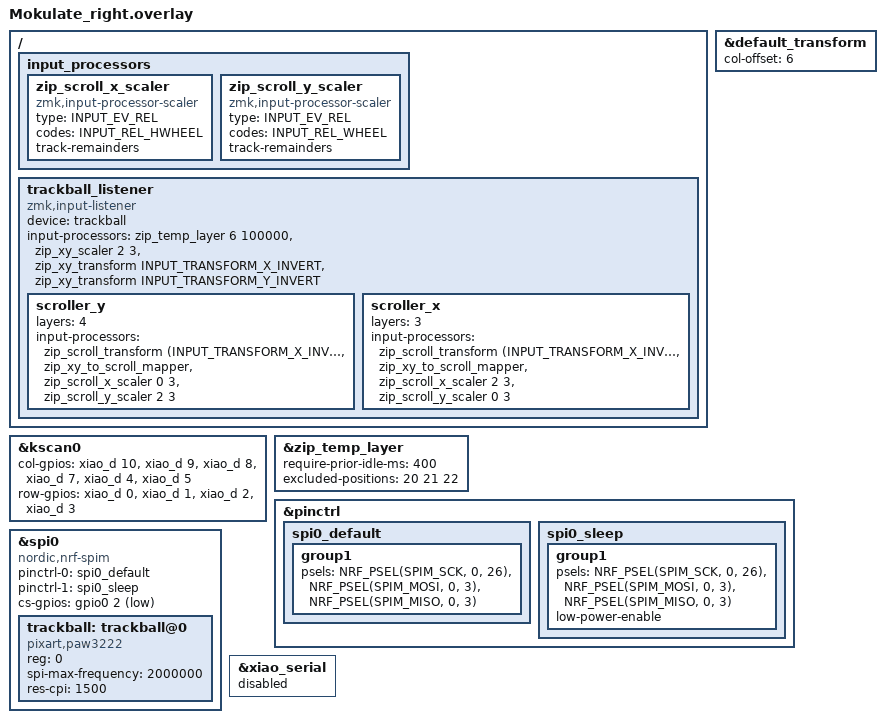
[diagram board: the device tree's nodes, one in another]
#include "Mokulate.dtsi"
#include <input/processors.dtsi>
#include <dt-bindings/zmk/input_transform.h>

&default_transform {
    col-offset = <6>;
};

&kscan0 {
    col-gpios
        = <&xiao_d 10 GPIO_ACTIVE_HIGH>  /* Col0 */
        , <&xiao_d 9 GPIO_ACTIVE_HIGH>   /* Col1 */
        , <&xiao_d 8 GPIO_ACTIVE_HIGH>   /* Col2 */
        , <&xiao_d 7 GPIO_ACTIVE_HIGH>   /* Col3 */
        , <&xiao_d 4 GPIO_ACTIVE_HIGH>   /* Col4 */
        , <&xiao_d 5 GPIO_ACTIVE_HIGH>   /* Col5 */
        ;
    row-gpios
        = <&xiao_d 0 (GPIO_ACTIVE_HIGH | GPIO_PULL_DOWN)>  /* Row0 */
        , <&xiao_d 1 (GPIO_ACTIVE_HIGH | GPIO_PULL_DOWN)>  /* Row1 */
        , <&xiao_d 2 (GPIO_ACTIVE_HIGH | GPIO_PULL_DOWN)>  /* Row2 */
        , <&xiao_d 3 (GPIO_ACTIVE_HIGH | GPIO_PULL_DOWN)>  /* Row3 */
        ;
};

// AMLから離脱しないキー
&zip_temp_layer {
    require-prior-idle-ms = <400>;
    excluded-positions = <
        20
        21
        22
    >;
};

/ {
    input_processors {
        zip_scroll_x_scaler: zip_scroll_x_scaler {
            compatible = "zmk,input-processor-scaler";
            #input-processor-cells = <2>;
            type = <INPUT_EV_REL>;
            codes = <INPUT_REL_HWHEEL>;
            track-remainders;
        };
        zip_scroll_y_scaler: zip_scroll_y_scaler {
            compatible = "zmk,input-processor-scaler";
            #input-processor-cells = <2>;
            type = <INPUT_EV_REL>;
            codes = <INPUT_REL_WHEEL>;
            track-remainders;
        };
    };
};

/ {
    trackball_listener: trackball_listener {
        status = "okay";
        compatible = "zmk,input-listener";
        device = <&trackball>;

        input-processors = <
            &zip_temp_layer 6 100000 // AMLレイヤー、タイムアウト時間
            &zip_xy_scaler 2 3 // カーソル移動量2/3倍
            &zip_xy_transform INPUT_TRANSFORM_X_INVERT // カーソルの移動方向調整
            &zip_xy_transform INPUT_TRANSFORM_Y_INVERT // カーソルの移動方向調整
        >;
    };
};

&trackball_listener {
    scroller_y {
        layers = <4>; // 縦スクロールレイヤー
        input-processors = <
            // &scroll_runtime_input_processor
            &zip_scroll_transform (INPUT_TRANSFORM_X_INVERT) // スクロール方向調整
            &zip_xy_to_scroll_mapper
            &zip_scroll_x_scaler 0 3 // X軸スクロール量0/3倍
            &zip_scroll_y_scaler 2 3 // Y軸スクロール量2/3倍
        >;
    };
    scroller_x {
        layers = <3>; // 横スクロールレイヤー
        input-processors = <
            &zip_scroll_transform (INPUT_TRANSFORM_X_INVERT) // スクロール方向調整
            &zip_xy_to_scroll_mapper
            &zip_scroll_x_scaler 2 3 // X軸スクロール量2/3倍
            &zip_scroll_y_scaler 0 3 // Y軸スクロール量0/3倍
        >;
    };
};

&pinctrl {
    spi0_default: spi0_default {
        group1 {
            // SCK=D8(P0.26), MOSI=D10(P0.03), MISO=D10(P0.03) ※3線式のためMOSI/MISOを共通化
            psels = <NRF_PSEL(SPIM_SCK, 0, 26)>,
                    <NRF_PSEL(SPIM_MOSI, 0, 3)>,
                    <NRF_PSEL(SPIM_MISO, 0, 3)>;
        };
    };

    spi0_sleep: spi0_sleep {
        group1 {
            psels = <NRF_PSEL(SPIM_SCK, 0, 26)>,
                    <NRF_PSEL(SPIM_MOSI, 0, 3)>,
                    <NRF_PSEL(SPIM_MISO, 0, 3)>;
            low-power-enable;
        };
    };
};

&spi0 {
    status = "okay";
    compatible = "nordic,nrf-spim";
    pinctrl-0 = <&spi0_default>;
    pinctrl-1 = <&spi0_sleep>;
    pinctrl-names = "default", "sleep";
    cs-gpios = <&gpio0 2 GPIO_ACTIVE_LOW>;

    trackball: trackball@0 {
        status = "okay";
        compatible = "pixart,paw3222";
        reg = <0>;
        spi-max-frequency = <2000000>;
        // irq-gpios = <&gpio0 2 (GPIO_ACTIVE_LOW | GPIO_PULL_UP)>;
        res-cpi = <1500>;
    };
};

&xiao_serial { status = "disabled"; };
